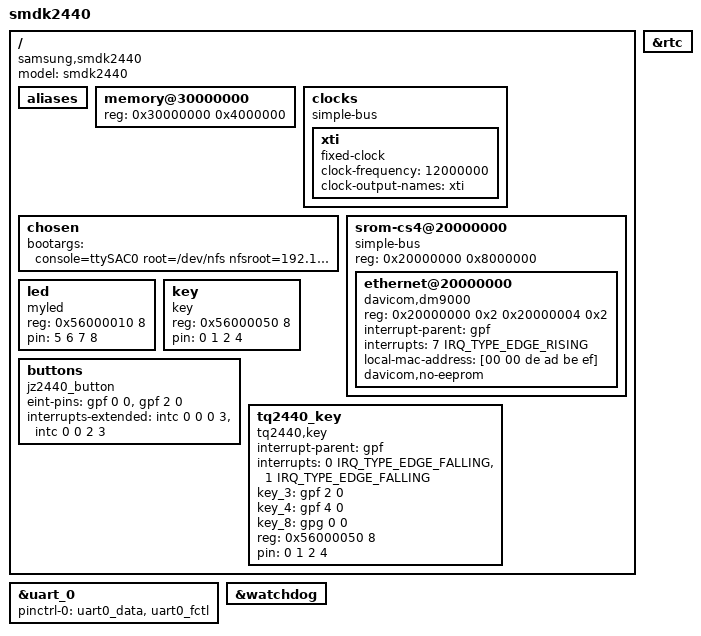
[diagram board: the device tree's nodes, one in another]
// SPDX-License-Identifier: GPL-2.0
/*
 * SAMSUNG SMDK2416 board device tree source
 *
 * Copyright (c) 2013 Heiko Stuebner <heiko@sntech.de>
 */

/dts-v1/;
#include "s3c2440.dtsi"
#include "/home/zhoubo/desktop/Linux内核移植/tq2440/linux-4.19-rc3/include/dt-bindings/interrupt-controller/irq.h"


/ {
	model = "smdk2440";
	compatible = "samsung,smdk2440";

	aliases {
	//	i2c1 = &i2c_gpio_1;
	}; 

	memory@30000000 {
		device_type = "memory";
		reg =  <0x30000000 0x4000000>;
	};
	clocks {
		compatible = "simple-bus";
		xti: xti {
			compatible = "fixed-clock";
			clock-frequency = <12000000>;
			clock-output-names = "xti";
			#clock-cells = <0>;
		};
	};
	
	chosen {
		//for tq2440
		bootargs = "console=ttySAC0 root=/dev/nfs nfsroot=192.168.1.8:/work/nfs_4.19-rc3 ip=192.168.1.6:192.168.1.8:192.168.1.6:255.255.255.0:SKY2440.embedsky.net:eth0:off";                  
	};
//for dm9000
	srom-cs4@20000000 {
		compatible = "simple-bus";
		#address-cells = <1>;
		#size-cells = <1>;
		reg = <0x20000000 0x8000000>;
		ranges;
							
		ethernet@20000000 {
			compatible = "davicom,dm9000";
			reg = <0x20000000 0x2 0x20000004 0x2>;
			interrupt-parent = <&gpf>;
			interrupts = <7 IRQ_TYPE_EDGE_RISING>;
			local-mac-address = [00 00 de ad be ef];
			davicom,no-eeprom;
		};
	};
	led {
		compatible = "myled";
		reg = <0x56000010 8>;
		pin = <5 6 7 8>;
	};
	key {
		compatible = "key";
		reg = <0x56000050 8>;
		pin = <0 1 2 4>;
	};
//for tq2440 exint
	/*
	interrupt-controller@4a000000 {
		compatible = "samsung,s3c2410-irq";
		reg = <0x4a000000 0x100>;
		interrupt-controller;
		#interrupt-cells = <0x4>;
		phandle = <0x1>;
	};
	*/
	buttons {
		compatible = "jz2440_button";
		eint-pins  = <&gpf 0 0>, <&gpf 2 0>; //<&gpg 3 0>, <&gpg 11 0>;
		interrupts-extended = <&intc 0 0 0 3>,
							  <&intc 0 0 2 3>;
							 // <&gpg 3 3>,
							 // <&gpg 11 3>;
	}; 
	tq2440_key {
        compatible = "tq2440,key";
        interrupt-parent = <&gpf>;
        interrupts = <0 IRQ_TYPE_EDGE_FALLING>, <1 IRQ_TYPE_EDGE_FALLING>;
        key_3 = <&gpf 2 0>;
        key_4 = <&gpf 4 0>;
        key_8 = <&gpg 0 0>;
		reg = <0x56000050 8>;
		pin = <0 1 2 4>;
    };

};
&rtc {
	status = "okay";
};
/*
&sdhci_0 {
	pinctrl-names = "default";
	pinctrl-0 = <&sd1_clk>, <&sd1_cmd>,
			<&sd1_bus1>, <&sd1_bus4>;
	bus-width = <4>;
	broken-cd;
	status = "okay";
};

&sdhci_1 {
	pinctrl-names = "default";
	pinctrl-0 = <&sd0_clk>, <&sd0_cmd>,
			<&sd0_bus1>, <&sd0_bus4>;
	bus-width = <4>;
	cd-gpios = <&gpf 1 0>;
	cd-inverted;
	status = "okay";
};
*/
&uart_0 {
	status = "okay";
	pinctrl-names = "default";
	pinctrl-0 = <&uart0_data>, <&uart0_fctl>;
};
/*
&uart_1 {
	status = "okay";
	pinctrl-names = "default";
	pinctrl-0 = <&uart1_data>, <&uart1_fctl>;
};

&uart_2 {
	status = "okay";
	pinctrl-names = "default";
	pinctrl-0 = <&uart2_data>;
};

&uart_3 {
	status = "okay";
	pinctrl-names = "default";
	pinctrl-0 = <&uart3_data>;
};
*/
&watchdog {
	status = "okay";
};
